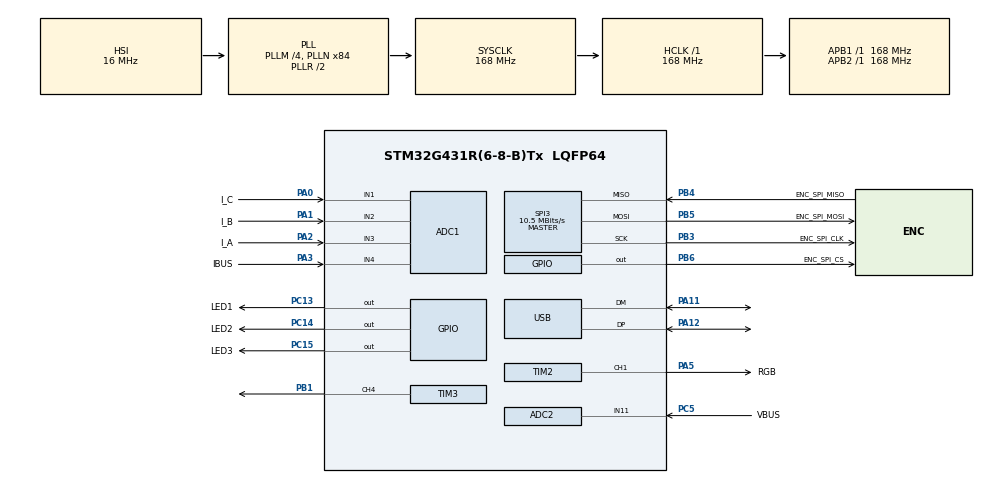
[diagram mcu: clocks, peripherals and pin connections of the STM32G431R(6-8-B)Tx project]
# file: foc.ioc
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ADC1.Channel-0\#ChannelRegularConversion=ADC_CHANNEL_1
ADC1.NbrOfConversionFlag=1
ADC1.OffsetNumber-0\#ChannelRegularConversion=ADC_OFFSET_NONE
ADC1.Rank-0\#ChannelRegularConversion=1
ADC1.SamplingTime-0\#ChannelRegularConversion=ADC_SAMPLETIME_2CYCLES_5
ADC1.master=1
ADC2.Channel-0\#ChannelRegularConversion=ADC_CHANNEL_11
ADC2.NbrOfConversionFlag=1
ADC2.OffsetNumber-0\#ChannelRegularConversion=ADC_OFFSET_NONE
ADC2.Rank-0\#ChannelRegularConversion=1
ADC2.SamplingTime-0\#ChannelRegularConversion=ADC_SAMPLETIME_2CYCLES_5
Dma.Request0=TIM2_CH1
Dma.Request1=TIM3_CH4
Dma.TIM2_CH1.0.Direction=DMA_MEMORY_TO_PERIPH
Dma.TIM2_CH1.0.EventEnable=DISABLE
Dma.TIM2_CH1.0.Instance=DMA1_Channel1
Dma.TIM2_CH1.0.MemDataAlignment=DMA_MDATAALIGN_WORD
Dma.TIM2_CH1.0.MemInc=DMA_MINC_ENABLE
Dma.TIM2_CH1.0.Mode=DMA_CIRCULAR
Dma.TIM2_CH1.0.PeriphDataAlignment=DMA_PDATAALIGN_WORD
Dma.TIM2_CH1.0.PeriphInc=DMA_PINC_DISABLE
Dma.TIM2_CH1.0.Polarity=HAL_DMAMUX_REQ_GEN_RISING
Dma.TIM2_CH1.0.Priority=DMA_PRIORITY_HIGH
Dma.TIM2_CH1.0.RequestNumber=1
Dma.TIM2_CH1.0.SignalID=NONE
Dma.TIM2_CH1.0.SyncEnable=DISABLE
Dma.TIM2_CH1.0.SyncPolarity=HAL_DMAMUX_SYNC_NO_EVENT
Dma.TIM2_CH1.0.SyncRequestNumber=1
Dma.TIM2_CH1.0.SyncSignalID=NONE
Dma.TIM3_CH4.1.Direction=DMA_MEMORY_TO_PERIPH
Dma.TIM3_CH4.1.EventEnable=DISABLE
Dma.TIM3_CH4.1.Instance=DMA1_Channel2
Dma.TIM3_CH4.1.MemDataAlignment=DMA_MDATAALIGN_HALFWORD
Dma.TIM3_CH4.1.MemInc=DMA_MINC_ENABLE
Dma.TIM3_CH4.1.Mode=DMA_NORMAL
Dma.TIM3_CH4.1.PeriphDataAlignment=DMA_PDATAALIGN_HALFWORD
Dma.TIM3_CH4.1.PeriphInc=DMA_PINC_DISABLE
Dma.TIM3_CH4.1.Polarity=HAL_DMAMUX_REQ_GEN_RISING
Dma.TIM3_CH4.1.Priority=DMA_PRIORITY_LOW
Dma.TIM3_CH4.1.RequestNumber=1
Dma.TIM3_CH4.1.SignalID=NONE
Dma.TIM3_CH4.1.SyncEnable=DISABLE
Dma.TIM3_CH4.1.SyncPolarity=HAL_DMAMUX_SYNC_NO_EVENT
Dma.TIM3_CH4.1.SyncRequestNumber=1
Dma.TIM3_CH4.1.SyncSignalID=NONE
FREERTOS.Tasks01=defaultTask,24,128,StartDefaultTask,Default,NULL,Dynamic,NULL,NULL
Mcu.Family=STM32G4
Mcu.Name=STM32G431R(6-8-B)Tx
Mcu.Package=LQFP64
NVIC.DMA1_Channel1_IRQn=true\:5\:0\:false\:false\:true\:true\:false\:true\:true
NVIC.DMA1_Channel2_IRQn=true\:5\:0\:false\:false\:true\:true\:false\:true\:true
NVIC.PriorityGroup=NVIC_PRIORITYGROUP_4
NVIC.TIM6_DAC_IRQn=true\:15\:0\:false\:false\:true\:false\:false\:true\:true
NVIC.TimeBase=TIM6_DAC_IRQn
NVIC.TimeBaseIP=TIM6
NVIC.USB_LP_IRQn=true\:5\:0\:false\:false\:true\:true\:false\:true\:true
PA0.GPIO_Label=I_C
PA0.Mode=IN1-Single-Ended
PA0.Signal=ADC1_IN1
PA1.GPIO_Label=I_B
PA1.Mode=IN2-Single-Ended
PA1.Signal=ADC1_IN2
PA11.Mode=Device
PA11.Signal=USB_DM
PA12.Mode=Device
PA12.Signal=USB_DP
PA13.Mode=Serial_Wire
PA13.Signal=SYS_JTMS-SWDIO
PA14.Mode=Serial_Wire
PA14.Signal=SYS_JTCK-SWCLK
PA2.GPIO_Label=I_A
PA2.Mode=IN3-Single-Ended
PA2.Signal=ADC1_IN3
PA3.GPIO_Label=IBUS
PA3.Mode=IN4-Single-Ended
PA3.Signal=ADC1_IN4
PA5.GPIO_Label=RGB
PA5.Signal=S_TIM2_CH1
PB1.Signal=S_TIM3_CH4
PB3.GPIO_Label=ENC_SPI_CLK
PB3.Mode=Full_Duplex_Master
PB3.Signal=SPI3_SCK
PB4.GPIO_Label=ENC_SPI_MISO
PB4.Mode=Full_Duplex_Master
PB4.Signal=SPI3_MISO
PB5.GPIO_Label=ENC_SPI_MOSI
PB5.Mode=Full_Duplex_Master
PB5.Signal=SPI3_MOSI
PB6.GPIO_Label=ENC_SPI_CS
PB6.Signal=GPIO_Output
PC13.GPIO_Label=LED1
PC13.Signal=GPIO_Output
PC14-OSC32_IN.GPIO_Label=LED2
PC14-OSC32_IN.Signal=GPIO_Output
PC15-OSC32_OUT.GPIO_Label=LED3
PC15-OSC32_OUT.Signal=GPIO_Output
PC5.GPIO_Label=VBUS
PC5.Mode=IN11-Single-Ended
PC5.Signal=ADC2_IN11
ProjectManager.HeapSize=0x200
ProjectManager.StackSize=0x400
ProjectManager.TargetToolchain=MDK-ARM V5.32
RCC.ADC12Freq_Value=168000000
RCC.AHBFreq_Value=168000000
RCC.APB1Freq_Value=168000000
RCC.APB1TimFreq_Value=168000000
RCC.APB2Freq_Value=168000000
RCC.APB2TimFreq_Value=168000000
RCC.CK48CLockSelection=RCC_USBCLKSOURCE_HSI48
RCC.CortexFreq_Value=168000000
RCC.EXTERNAL_CLOCK_VALUE=12288000
RCC.HCLKFreq_Value=168000000
RCC.HSE_VALUE=25000000
RCC.HSI48_VALUE=48000000
RCC.HSI_VALUE=16000000
RCC.LSE_VALUE=32768
RCC.PLLM=RCC_PLLM_DIV4
RCC.PLLN=84
RCC.SYSCLKFreq_VALUE=168000000
RCC.SYSCLKSource=RCC_SYSCLKSOURCE_PLLCLK
RCC.USBFreq_Value=48000000
RCC.VCOOutputFreq_Value=336000000
SH.S_TIM2_CH1.0=TIM2_CH1,PWM Generation1 CH1
SH.S_TIM3_CH4.0=TIM3_CH4,PWM Generation4 CH4
SPI3.BaudRatePrescaler=SPI_BAUDRATEPRESCALER_16
SPI3.CLKPhase=SPI_PHASE_2EDGE
SPI3.CLKPolarity=SPI_POLARITY_HIGH
SPI3.CalculateBaudRate=10.5 MBits/s
SPI3.Direction=SPI_DIRECTION_2LINES
SPI3.Mode=SPI_MODE_MASTER
SPI3.VirtualType=VM_MASTER
TIM2.Channel-PWM\ Generation1\ CH1=TIM_CHANNEL_1
TIM2.PeriodNoDither=209
TIM2.PulseNoDither_1=139
TIM3.Channel-PWM\ Generation4\ CH4=TIM_CHANNEL_4
TIM3.PeriodNoDither=209
TIM3.PulseNoDither_4=139
USB_DEVICE.CLASS_NAME_FS=CDC
USB_DEVICE.VirtualMode=Cdc
USB_DEVICE.VirtualModeFS=Cdc_FS
VP_FREERTOS_VS_CMSIS_V2.Mode=CMSIS_V2
VP_SYS_VS_DBSignals.Mode=DisableDeadBatterySignals
VP_SYS_VS_tim6.Mode=TIM6
VP_USB_DEVICE_VS_USB_DEVICE_CDC_FS.Mode=CDC_FS
board=custom

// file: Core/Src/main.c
/* USER CODE BEGIN Header */
/**
  ******************************************************************************
  * @file           : main.c
  * @brief          : Main program body
  ******************************************************************************
  * @attention
  *
  * Copyright (c) 2023 STMicroelectronics.
  * All rights reserved.
  *
  * This software is licensed under terms that can be found in the LICENSE file
  * in the root directory of this software component.
  * If no LICENSE file comes with this software, it is provided AS-IS.
  *
  ******************************************************************************
  */
/* USER CODE END Header */
#include "main.h"
#include "cmsis_os.h"
#include "adc.h"
#include "dma.h"
#include "spi.h"
#include "tim.h"
#include "usb_device.h"
#include "gpio.h"

/* USER CODE BEGIN Includes */
#include "main_help.h"
/* USER CODE END Includes */

void SystemClock_Config(void);
void MX_FREERTOS_Init(void);

int main(void)
{

  /* MCU Configuration--------------------------------------------------------*/

  /* Reset of all peripherals, Initializes the Flash interface and the Systick. */
  HAL_Init();

  /* Configure the system clock */
  SystemClock_Config();

  /* Initialize all configured peripherals */
  MX_GPIO_Init();
  MX_DMA_Init();
  MX_USB_Device_Init();
  MX_TIM2_Init();
  MX_TIM3_Init();
  MX_SPI3_Init();
  MX_ADC1_Init();
  MX_ADC2_Init();
  /* USER CODE BEGIN 2 */

	rtos_main();
	//vofa_init();
  /* USER CODE END 2 */

  /* Init scheduler */
  osKernelInitialize();  /* Call init function for freertos objects (in freertos.c) */
  MX_FREERTOS_Init();

  /* Start scheduler */
  osKernelStart();
  /* We should never get here as control is now taken by the scheduler */
  /* Infinite loop */
  while (1)
  {

  }
}

void SystemClock_Config(void)
{
  RCC_OscInitTypeDef RCC_OscInitStruct = {0};
  RCC_ClkInitTypeDef RCC_ClkInitStruct = {0};

  /** Configure the main internal regulator output voltage
  */
  HAL_PWREx_ControlVoltageScaling(PWR_REGULATOR_VOLTAGE_SCALE1_BOOST);

  /** Initializes the RCC Oscillators according to the specified parameters
  * in the RCC_OscInitTypeDef structure.
  */
  RCC_OscInitStruct.OscillatorType = RCC_OSCILLATORTYPE_HSI|RCC_OSCILLATORTYPE_HSI48;
  RCC_OscInitStruct.HSIState = RCC_HSI_ON;
  RCC_OscInitStruct.HSICalibrationValue = RCC_HSICALIBRATION_DEFAULT;
  RCC_OscInitStruct.HSI48State = RCC_HSI48_ON;
  RCC_OscInitStruct.PLL.PLLState = RCC_PLL_ON;
  RCC_OscInitStruct.PLL.PLLSource = RCC_PLLSOURCE_HSI;
  RCC_OscInitStruct.PLL.PLLM = RCC_PLLM_DIV4;
  RCC_OscInitStruct.PLL.PLLN = 84;
  RCC_OscInitStruct.PLL.PLLP = RCC_PLLP_DIV2;
  RCC_OscInitStruct.PLL.PLLQ = RCC_PLLQ_DIV2;
  RCC_OscInitStruct.PLL.PLLR = RCC_PLLR_DIV2;
  if (HAL_RCC_OscConfig(&RCC_OscInitStruct) != HAL_OK)
  {
    Error_Handler();
  }

  /** Initializes the CPU, AHB and APB buses clocks
  */
  RCC_ClkInitStruct.ClockType = RCC_CLOCKTYPE_HCLK|RCC_CLOCKTYPE_SYSCLK
                              |RCC_CLOCKTYPE_PCLK1|RCC_CLOCKTYPE_PCLK2;
  RCC_ClkInitStruct.SYSCLKSource = RCC_SYSCLKSOURCE_PLLCLK;
  RCC_ClkInitStruct.AHBCLKDivider = RCC_SYSCLK_DIV1;
  RCC_ClkInitStruct.APB1CLKDivider = RCC_HCLK_DIV1;
  RCC_ClkInitStruct.APB2CLKDivider = RCC_HCLK_DIV1;

  if (HAL_RCC_ClockConfig(&RCC_ClkInitStruct, FLASH_LATENCY_4) != HAL_OK)
  {
    Error_Handler();
  }
}

void HAL_TIM_PeriodElapsedCallback(TIM_HandleTypeDef *htim)
{
  if (htim->Instance == TIM6) {
    HAL_IncTick();
  }
}

void Error_Handler(void)
{
  __disable_irq();
  while (1)
  {
  }
}
